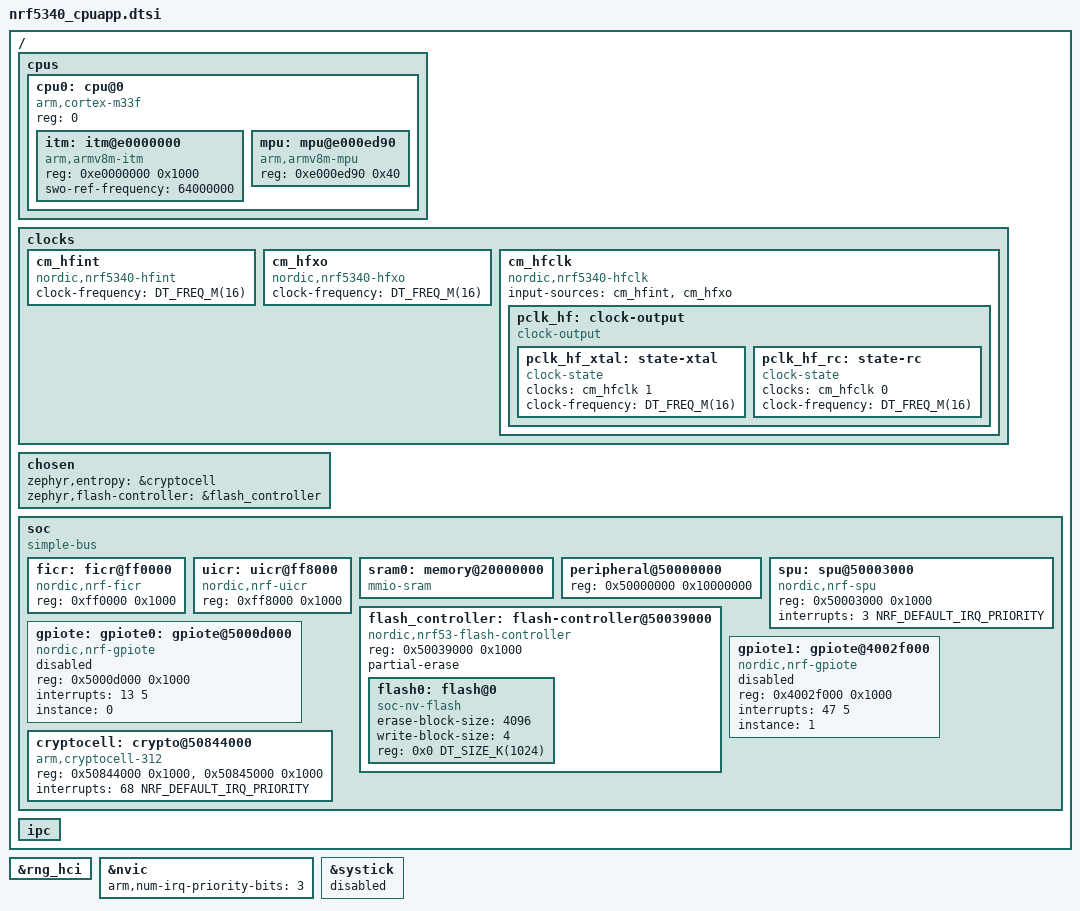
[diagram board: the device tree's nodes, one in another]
/*
 * Copyright (c) 2019 Nordic Semiconductor ASA
 *
 * SPDX-License-Identifier: Apache-2.0
 */

#include <arm/armv8-m.dtsi>
#include <nordic/nrf_common.dtsi>
#include <zephyr/dt-bindings/adc/nrf-saadc.h>
#include <arm/nordic/nrf5340_clocks.dtsi>

/ {
	cpus {
		#address-cells = <1>;
		#size-cells = <0>;

		cpu0: cpu@0 {
			device_type = "cpu";
			compatible = "arm,cortex-m33f";
			reg = <0>;
			#address-cells = <1>;
			#size-cells = <1>;

			itm: itm@e0000000 {
				compatible = "arm,armv8m-itm";
				reg = <0xe0000000 0x1000>;
				swo-ref-frequency = <64000000>;
			};

			mpu: mpu@e000ed90 {
				compatible = "arm,armv8m-mpu";
				reg = <0xe000ed90 0x40>;
			};
		};
	};

	/*
	 * Clock-management view of the nRF5340 HFCLK domain, showcasing the
	 * clock-states concept (RFC zephyrproject-rtos/zephyr#89124).
	 *
	 * HFINT (internal RC) and HFXO (crystal) are root clocks feeding the
	 * HFCLK source multiplexer. Peripherals tap the multiplexer through the
	 * "clock-output" leaf node (pclk_hf) and select their source by applying
	 * a clock state. Both roots report the peripheral-visible frequency; they
	 * differ only in accuracy (HFXO is crystal-accurate).
	 */
	clocks {
		cm_hfint: cm_hfint {
			compatible = "nordic,nrf5340-hfint";
			#clock-cells = <0>;
			clock-frequency = <DT_FREQ_M(16)>;
		};

		cm_hfxo: cm_hfxo {
			compatible = "nordic,nrf5340-hfxo";
			#clock-cells = <0>;
			clock-frequency = <DT_FREQ_M(16)>;
		};

		cm_hfclk: cm_hfclk {
			compatible = "nordic,nrf5340-hfclk";
			#clock-cells = <1>;
			/* index 0 = HFINT (RC), index 1 = HFXO (crystal) */
			input-sources = <&cm_hfint &cm_hfxo>;

			pclk_hf: clock-output {
				compatible = "clock-output";
				#clock-cells = <0>;

				/*
				 * Example clock states a consumer can apply.
				 * "xtal" drives HFCLK from the crystal (HFXO,
				 * accurate); "rc" drives it from the internal RC
				 * (HFINT, low power). Both produce the same
				 * peripheral frequency.
				 */
				pclk_hf_xtal: state-xtal {
					compatible = "clock-state";
					clocks = <&cm_hfclk 1>; /* HFXO */
					clock-frequency = <DT_FREQ_M(16)>;
				};

				pclk_hf_rc: state-rc {
					compatible = "clock-state";
					clocks = <&cm_hfclk 0>; /* HFINT */
					clock-frequency = <DT_FREQ_M(16)>;
				};
			};
		};
	};

	chosen {
		zephyr,entropy = &cryptocell;
		zephyr,flash-controller = &flash_controller;
	};

	soc {
		compatible = "simple-bus";

		ficr: ficr@ff0000 {
			compatible = "nordic,nrf-ficr";
			reg = <0xff0000 0x1000>;
			#nordic,ficr-cells = <1>;
			status = "okay";
		};

		uicr: uicr@ff8000 {
			compatible = "nordic,nrf-uicr";
			reg = <0xff8000 0x1000>;
			ranges = <0x0 0xff8000 0x1000>;
			status = "okay";
			#address-cells = <1>;
			#size-cells = <1>;
		};

		sram0: memory@20000000 {
			compatible = "mmio-sram";
			#address-cells = <1>;
			#size-cells = <1>;
		};

		peripheral@50000000 {
			reg = <0x50000000 0x10000000>;
			#address-cells = <1>;
			#size-cells = <1>;
			ranges = <0x0 0x50000000 0x10000000>,
				 <0x10000000 0x10000000 0x10000000>;

			/* Common nRF5340 Application MCU
			 * peripheral description
			 */
			#include "nrf5340_cpuapp_peripherals.dtsi"
		};

		flash_controller: flash-controller@50039000 {
			compatible = "nordic,nrf53-flash-controller";
			reg = <0x50039000 0x1000>;
			ranges;
			partial-erase;
			#address-cells = <1>;
			#size-cells = <1>;

			flash0: flash@0 {
				compatible = "soc-nv-flash";
				erase-block-size = <4096>;
				write-block-size = <4>;
				reg = <0x0 DT_SIZE_K(1024)>;
				ranges = <0x0 0x0 DT_SIZE_K(1024)>;
				status = "okay";
				#address-cells = <1>;
				#size-cells = <1>;
			};
		};

		/* Additional Secure peripherals */

		spu: spu@50003000 {
			compatible = "nordic,nrf-spu";
			reg = <0x50003000 0x1000>;
			interrupts = <3 NRF_DEFAULT_IRQ_PRIORITY>;
			status = "okay";
		};

		/*
		 * GPIOTE0 is always accessible as a secure peripheral,
		 * so we give it the 'gpiote' label for use when building
		 * code for this target.
		 */
		gpiote: gpiote0: gpiote@5000d000 {
			compatible = "nordic,nrf-gpiote";
			reg = <0x5000d000 0x1000>;
			interrupts = <13 5>;
			status = "disabled";
			instance = <0>;
		};

		/* Additional Non-Secure GPIOTE instance */
		gpiote1: gpiote@4002f000 {
			compatible = "nordic,nrf-gpiote";
			reg = <0x4002f000 0x1000>;
			interrupts = <47 5>;
			status = "disabled";
			instance = <1>;
		};

		cryptocell: crypto@50844000 {
			compatible = "arm,cryptocell-312";
			reg = <0x50844000 0x1000>, <0x50845000 0x1000>;
			reg-names = "wrapper", "core";
			interrupts = <68 NRF_DEFAULT_IRQ_PRIORITY>;
			status = "okay";
		};
	};

	/* Default IPC description */
	ipc {
		#include "nrf5340_cpuapp_ipc.dtsi"
	};
};

&rng_hci {
	/* Application core has no accessible RNG peripheral */
	status = "okay";
};

&nvic {
	arm,num-irq-priority-bits = <3>;
};

&systick {
	/* Use RTC for system clock, instead of SysTick. */
	status = "disabled";
};
